# ESP32S31_RADIO register map
Vendor: Espressif; Series: ESP32-S31; File version: 3.52
Registers are 32-bit, read-write, no defined reset value unless marked. A register's access mark holds for its fields unless they carry their own. Offsets are from the block's base; [hi:lo] are bit positions; lines under a group give offsets from that group; {n}, {i} and the like mark numbered series; 'fields as' and 'values as' point back to an identical list.

## WIFI_MAC_REGDMA_CONTROL — Shared WDEVPWR control word. The channel-change leaf proves the REGDMA selector, while complete modem-power leaves prove the wake-protect lead time and TBTT auto-period fields. Hardware interactions between these fields remain unqualified.
Base 0x2010D83C
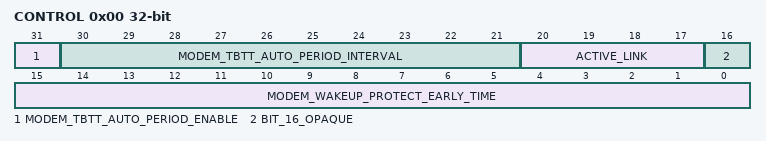
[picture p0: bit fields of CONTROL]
0x00 CONTROL — Project-assigned name. Shared REGDMA and modem wakeup configuration word. Every promoted field has a complete independent setter; their combined hardware lifecycle is not inferred.
  [31] MODEM_TBTT_AUTO_PERIOD_ENABLE — Project-assigned name. The dedicated enable and disable leaves set or clear bit 31.
  [30:21] MODEM_TBTT_AUTO_PERIOD_INTERVAL — Project-assigned name. libpp[hal_pwr.o]::pwr_hal_set_mac_modem_tbtt_auto_period_interval replaces bits 30:21 from the low ten argument bits.
  [20:17] ACTIVE_LINK — Project-assigned name. Four-bit Wi-Fi MAC REGDMA link selector; the active no-power-save channel restart writes four. Leaving zero after retuning caused intermittent authentication ACK timeouts.
    on write: 4=WIFI_NO_POWER_SAVE (REGDMA link selected by the qualified Wi-Fi no-power-save restart.)
  [16] BIT_16_OPAQUE — Opaque: meaning not established.
  [15:0] MODEM_WAKEUP_PROTECT_EARLY_TIME — Project-assigned name. libpp[hal_pwr.o]::pwr_hal_set_mac_modem_state_wakeup_protect_early_time replaces the low sixteen bits.

## WIFI_MAC_KEY_TABLE — Twenty-five entries of ten 32-bit words. Complete hal_crypto_clr_key_entry proves the 0x28-byte stride and all ten ordered stores; set/get leaves prove the peer/control/key layout: the peer address and control word, four words of temporal key and four words the CCMP transaction only clears.
Base 0x20105800
{0x0+0x28*i} ENTRY_PEER_LOW{i} (i=0..24) — Project-assigned name. Word zero of an entry: the first four peer address bytes, little endian.
  [31:0] PEER_LOW — Project-assigned name. Peer MAC address bytes 0 to 3, or 0xffffffff for a group key.
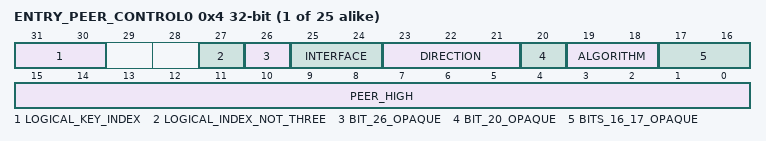
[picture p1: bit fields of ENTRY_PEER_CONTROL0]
{0x4+0x28*i} ENTRY_PEER_CONTROL{i} (i=0..24) — Project-assigned name. Word one of an entry: the last two peer address bytes and the control halfword hal_crypto_set_key_entry composes.
  [31:30] LOGICAL_KEY_INDEX — Project-assigned name. Logical key slot: zero for a pairwise key, the key identifier for a group key.
  [27] LOGICAL_INDEX_NOT_THREE — Project-assigned name. Set unless the logical key index is three.
  [26] BIT_26_OPAQUE — Opaque: meaning not established. Bit the recovered CCMP transaction writes zero.
  [25:24] INTERFACE — Project-assigned name. Interface the key belongs to: 0 station, 1 access point.
  [23:21] DIRECTION — Project-assigned name. Key use selector: 3 for a pairwise key, 6 for a group key.
  [20] BIT_20_OPAQUE — Opaque: meaning not established. Bit the recovered CCMP transaction writes zero.
  [19:18] ALGORITHM — Project-assigned name. Cipher selector; 3 is CCMP.
  [17:16] BITS_16_17_OPAQUE — Opaque: meaning not established. Bits the recovered CCMP transaction writes zero.
  [15:0] PEER_HIGH — Project-assigned name. Peer MAC address bytes 4 and 5, or 0xffff for a group key.
{0x8+0x28*i} ENTRY_KEY_WORD_0{i} (i=0..24) — Project-assigned name. Temporal key bytes 0 to 3 of an entry, little endian.
  [31:0] VALUE — Project-assigned name. Four temporal key bytes.
{0xC+0x28*i} ENTRY_KEY_WORD_1{i} (i=0..24) — Project-assigned name. Temporal key bytes 4 to 7 of an entry, little endian.
  [31:0] VALUE — Project-assigned name. Four temporal key bytes.
{0x10+0x28*i} ENTRY_KEY_WORD_2{i} (i=0..24) — Project-assigned name. Temporal key bytes 8 to 11 of an entry, little endian.
  [31:0] VALUE — Project-assigned name. Four temporal key bytes.
{0x14+0x28*i} ENTRY_KEY_WORD_3{i} (i=0..24) — Project-assigned name. Temporal key bytes 12 to 15 of an entry, little endian.
  [31:0] VALUE — Project-assigned name. Four temporal key bytes.
{0x18+0x28*i} ENTRY_TAIL_WORD_0{i} (i=0..24) — Project-assigned name. Word the CCMP transaction only clears; its other users are not recovered.
  [31:0] VALUE — Project-assigned name. Cleared by hal_crypto_clr_key_entry.
{0x1C+0x28*i} ENTRY_TAIL_WORD_1{i} (i=0..24) — Project-assigned name. Word the CCMP transaction only clears; its other users are not recovered.
  fields as ENTRY_TAIL_WORD_00
{0x20+0x28*i} ENTRY_TAIL_WORD_2{i} (i=0..24) — Project-assigned name. Word the CCMP transaction only clears; its other users are not recovered.
  fields as ENTRY_TAIL_WORD_00
{0x24+0x28*i} ENTRY_TAIL_WORD_3{i} (i=0..24) — Project-assigned name. Word the CCMP transaction only clears; its other users are not recovered.
  fields as ENTRY_TAIL_WORD_00
